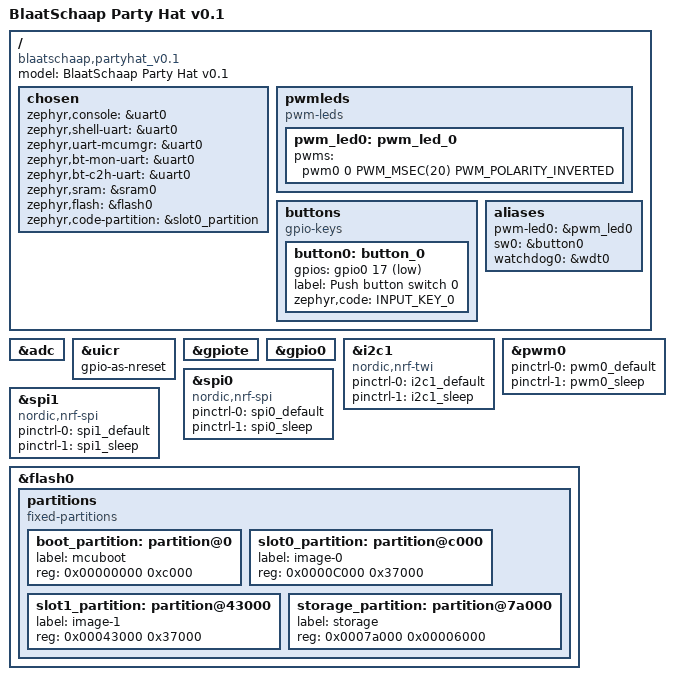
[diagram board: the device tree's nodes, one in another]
/*
 * Copyright (c) 2017 Shawn Nock <shawn@monadnock.ca>
 * Copyright (c) 2017 Linaro Limited
 *
 * SPDX-License-Identifier: Apache-2.0
 */

/dts-v1/;
#include <nordic/nrf52832_qfaa.dtsi>
#include "nrf52dk_nrf52832-pinctrl.dtsi"
#include <zephyr/dt-bindings/input/input-event-codes.h>

/ {
	model = "BlaatSchaap Party Hat v0.1";
	compatible = "blaatschaap,partyhat_v0.1";

	chosen {
		zephyr,console = &uart0;
		zephyr,shell-uart = &uart0;
		zephyr,uart-mcumgr = &uart0;
		zephyr,bt-mon-uart = &uart0;
		zephyr,bt-c2h-uart = &uart0;
		zephyr,sram = &sram0;
		zephyr,flash = &flash0;
		zephyr,code-partition = &slot0_partition;
	};

	pwmleds {
		compatible = "pwm-leds";
		pwm_led0: pwm_led_0 {
			pwms = <&pwm0 0 PWM_MSEC(20) PWM_POLARITY_INVERTED>;
		};
	};

	buttons {
		compatible = "gpio-keys";
		button0: button_0 {
			gpios = <&gpio0 17 (GPIO_PULL_UP | GPIO_ACTIVE_LOW)>;
			label = "Push button switch 0";
			zephyr,code = <INPUT_KEY_0>;
		};
	};

	/* These aliases are provided for compatibility with samples */
	aliases {
		pwm-led0 = &pwm_led0;
		sw0 = &button0;
		watchdog0 = &wdt0;
	};
};

&adc {
	status = "okay";
};

&uicr {
	gpio-as-nreset;
};

&gpiote {
	status = "okay";
};

&gpio0 {
	status = "okay";
};


&i2c1 {
	compatible = "nordic,nrf-twi";
	/* Cannot be used together with spi1. */
	/* status = "okay"; */
	pinctrl-0 = <&i2c1_default>;
	pinctrl-1 = <&i2c1_sleep>;
	pinctrl-names = "default", "sleep";
};

&pwm0 {
	status = "okay";
	pinctrl-0 = <&pwm0_default>;
	pinctrl-1 = <&pwm0_sleep>;
	pinctrl-names = "default", "sleep";
};

&spi0 {
	compatible = "nordic,nrf-spi";
	/* Cannot be used together with i2c0. */
	/* status = "okay"; */
	pinctrl-0 = <&spi0_default>;
	pinctrl-1 = <&spi0_sleep>;
	pinctrl-names = "default", "sleep";
};

&spi1 {
	compatible = "nordic,nrf-spi";
	status = "okay";
	pinctrl-0 = <&spi1_default>;
	pinctrl-1 = <&spi1_sleep>;
	pinctrl-names = "default", "sleep";
};


&flash0 {

	partitions {
		compatible = "fixed-partitions";
		#address-cells = <1>;
		#size-cells = <1>;

		boot_partition: partition@0 {
			label = "mcuboot";
			reg = <0x00000000 0xc000>;
		};
		slot0_partition: partition@c000 {
			label = "image-0";
			reg = <0x0000C000 0x37000>;
		};
		slot1_partition: partition@43000 {
			label = "image-1";
			reg = <0x00043000 0x37000>;
		};
		storage_partition: partition@7a000 {
			label = "storage";
			reg = <0x0007a000 0x00006000>;
		};
	};
};
